# j7am_pulsar1_periph_switch_cbass0_ISC register map
Vendor: Texas Instruments
Peripheral module from a debugger description file (folder J721S2).
Registers are 32-bit, read-write, reset 0x0 unless marked. A register's access mark holds for its fields unless they carry their own. Offsets are as the file gives them; lines under a group give offsets from that group; [hi:lo] are bit positions; {n}, {i} and the like mark numbered series; 'fields as' and 'values as' point back to an identical list; <NAME> marks a mode.

## j7am_pulsar1_periph_switch_cbass0_ISC
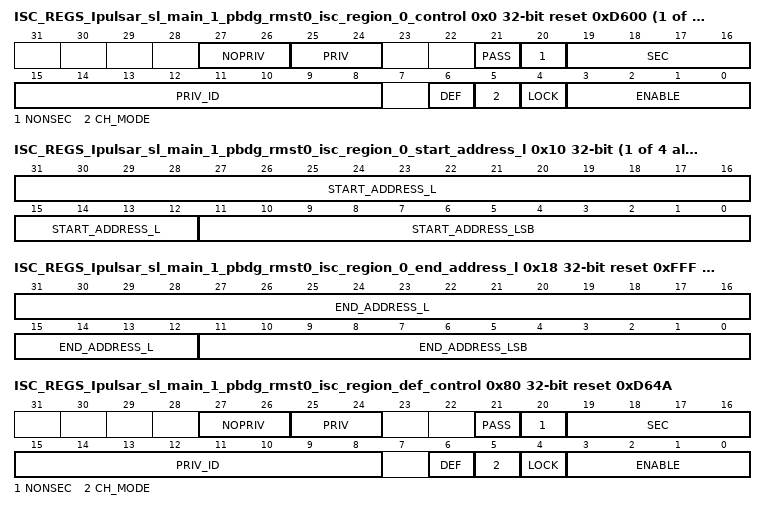
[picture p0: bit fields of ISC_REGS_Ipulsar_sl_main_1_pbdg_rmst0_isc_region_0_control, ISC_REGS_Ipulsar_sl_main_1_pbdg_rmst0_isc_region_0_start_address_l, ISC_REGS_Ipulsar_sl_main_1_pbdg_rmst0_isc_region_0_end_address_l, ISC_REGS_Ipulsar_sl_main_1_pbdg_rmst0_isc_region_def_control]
{0x0+0x20*i} ISC_REGS_Ipulsar_sl_main_1_pbdg_rmst0_isc_region_{i}_control access not given reset 0xD600 (i=0..3) — The ISC Region {i} Control Register defines the control fields for the master Ipulsar_sl_main_1.pbdg_rmst0 region {i} ISC.
  [27:26] NOPRIV rw — Clear output priv attribute. If each bit is set then the outgoing priv bit is cleared.
  [25:24] PRIV rw — Set outgoing priv attribute. If each bit is set then the outgoing priv bit is set.
  [21] PASS rw — No privID replacement, pass through value.
  [20] NONSEC rw — Make outgoing non-secure.
  [19:16] SEC rw — Make outgoing secure. A value of 0xA enables, others disable.
  [15:8] PRIV_ID rw
  [6] DEF ro — Default region indication. The default region is used when all other regions do not match.
  [5] CH_MODE rw — Enable channel mode to match region to a chanid value. Otherwise use address mode to match region to an address range.
  [4] LOCK — Lock region. Once set the region values cannot be modified. (access R/W1TS)
  [3:0] ENABLE rw — Enable region. A value of 0xA enables, others disable.
{0x10+0x20*i} ISC_REGS_Ipulsar_sl_main_1_pbdg_rmst0_isc_region_{i}_start_address_l (i=0..3) — The ISC Region {i} Start Address Low Register defines the start address bits 31 to 0 for the master Ipulsar_sl_main_1.pbdg_rmst0 region {i} ISC.
  [31:12] START_ADDRESS_L — Start address bits 31 to 12.
  [11:0] START_ADDRESS_LSB — Start address bits 11 to 0 must be 0 as address must be 4KB aligned in address mode. Can also be channel number in channel mode.
{0x14+0x20*i} ISC_REGS_Ipulsar_sl_main_1_pbdg_rmst0_isc_region_{i}_start_address_h (i=0..3) — The ISC Region {i} Start Address High Register defines the start address bits 47 to 32 for the master Ipulsar_sl_main_1.pbdg_rmst0 region {i} ISC.
  [15:0] START_ADDRESS_H — Start address bits 47 to 32.
{0x18+0x20*i} ISC_REGS_Ipulsar_sl_main_1_pbdg_rmst0_isc_region_{i}_end_address_l access per field reset 0xFFF (i=0..3) — The ISC Region {i} End Address Low Register defines the end included address bits 31 to 0 for the master Ipulsar_sl_main_1.pbdg_rmst0 region {i} ISC.
  [31:12] END_ADDRESS_L rw — End address bits 31 to 12 to include in the match.
  [11:0] END_ADDRESS_LSB ro — End address bits 11 to 0 are forced to Fs as address must be 4KB aligned.
{0x1C+0x20*i} ISC_REGS_Ipulsar_sl_main_1_pbdg_rmst0_isc_region_{i}_end_address_h (i=0..3) — The ISC Region {i} End Address High Register defines the end address bits 47 to 32 for the master Ipulsar_sl_main_1.pbdg_rmst0 region {i} ISC.
  [15:0] END_ADDRESS_H — End address bits 47 to 32.
0x80 ISC_REGS_Ipulsar_sl_main_1_pbdg_rmst0_isc_region_def_control access not given reset 0xD64A — The ISC Default Region Control Register defines the control fields for the master Ipulsar_sl_main_1.pbdg_rmst0 region 4 ISC.
  [27:26] NOPRIV rw — Clear output priv attribute. If each bit is set then the outgoing priv bit is cleared, else the bit is unchanged. Do not set both priv and nopriv for the same bit.
  [25:24] PRIV rw — Set outgoing priv attribute. If each bit is set then the outgoing priv bit is set, else the bit is unchanged. Do not set both priv and nopriv for the same bit.
  [21] PASS rw — No privID replacement. A value of 1 will pass through privid value. A value of 0 will replace privid with priv_id field value.
  [20] NONSEC rw — Make outgoing non-secure. A value of 1 forces secure clear, others do nothing. Do not set both sec and nonsec.
  [19:16] SEC rw — Make outgoing secure. A value of 0xA forces secure set, others do nothing. Do not set both sec and nonsec.
  [15:8] PRIV_ID rw — Priv ID value to use if pass is 0.
  [6] DEF ro — Default region indication. The default region is used when all other regions do not match.
  [5] CH_MODE ro — Enable channel mode to match region to a chanid value. Otherwise use address mode to match region to an address range.
  [4] LOCK — Lock region. Once set, the region values cannot be modified. (access R/W1TS)
  [3:0] ENABLE ro — Enable region. A value of 0xA enables, others disable.
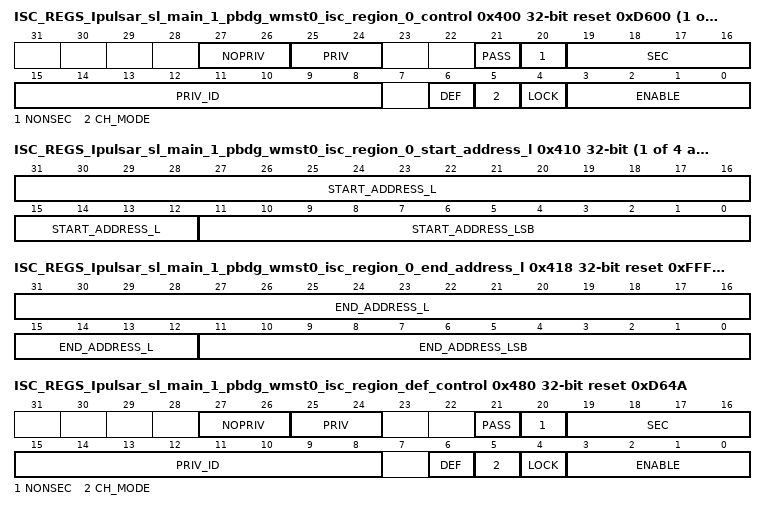
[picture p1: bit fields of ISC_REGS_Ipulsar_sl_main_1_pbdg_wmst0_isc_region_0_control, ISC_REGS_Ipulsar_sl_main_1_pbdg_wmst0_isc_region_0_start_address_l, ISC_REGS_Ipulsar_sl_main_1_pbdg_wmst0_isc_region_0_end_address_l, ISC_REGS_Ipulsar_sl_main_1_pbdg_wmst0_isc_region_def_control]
{0x400+0x20*i} ISC_REGS_Ipulsar_sl_main_1_pbdg_wmst0_isc_region_{i}_control access not given reset 0xD600 (i=0..3) — The ISC Region {i} Control Register defines the control fields for the master Ipulsar_sl_main_1.pbdg_wmst0 region {i} ISC.
  fields as ISC_REGS_Ipulsar_sl_main_1_pbdg_rmst0_isc_region_0_control
{0x410+0x20*i} ISC_REGS_Ipulsar_sl_main_1_pbdg_wmst0_isc_region_{i}_start_address_l (i=0..3) — The ISC Region {i} Start Address Low Register defines the start address bits 31 to 0 for the master Ipulsar_sl_main_1.pbdg_wmst0 region {i} ISC.
  fields as ISC_REGS_Ipulsar_sl_main_1_pbdg_rmst0_isc_region_0_start_address_l
{0x414+0x20*i} ISC_REGS_Ipulsar_sl_main_1_pbdg_wmst0_isc_region_{i}_start_address_h (i=0..3) — The ISC Region {i} Start Address High Register defines the start address bits 47 to 32 for the master Ipulsar_sl_main_1.pbdg_wmst0 region {i} ISC.
  [15:0] START_ADDRESS_H — Start address bits 47 to 32.
{0x418+0x20*i} ISC_REGS_Ipulsar_sl_main_1_pbdg_wmst0_isc_region_{i}_end_address_l access per field reset 0xFFF (i=0..3) — The ISC Region {i} End Address Low Register defines the end included address bits 31 to 0 for the master Ipulsar_sl_main_1.pbdg_wmst0 region {i} ISC.
  fields as ISC_REGS_Ipulsar_sl_main_1_pbdg_rmst0_isc_region_0_end_address_l
{0x41C+0x20*i} ISC_REGS_Ipulsar_sl_main_1_pbdg_wmst0_isc_region_{i}_end_address_h (i=0..3) — The ISC Region {i} End Address High Register defines the end address bits 47 to 32 for the master Ipulsar_sl_main_1.pbdg_wmst0 region {i} ISC.
  [15:0] END_ADDRESS_H — End address bits 47 to 32.
0x480 ISC_REGS_Ipulsar_sl_main_1_pbdg_wmst0_isc_region_def_control access not given reset 0xD64A — The ISC Default Region Control Register defines the control fields for the master Ipulsar_sl_main_1.pbdg_wmst0 region 4 ISC.
  fields as ISC_REGS_Ipulsar_sl_main_1_pbdg_rmst0_isc_region_def_control
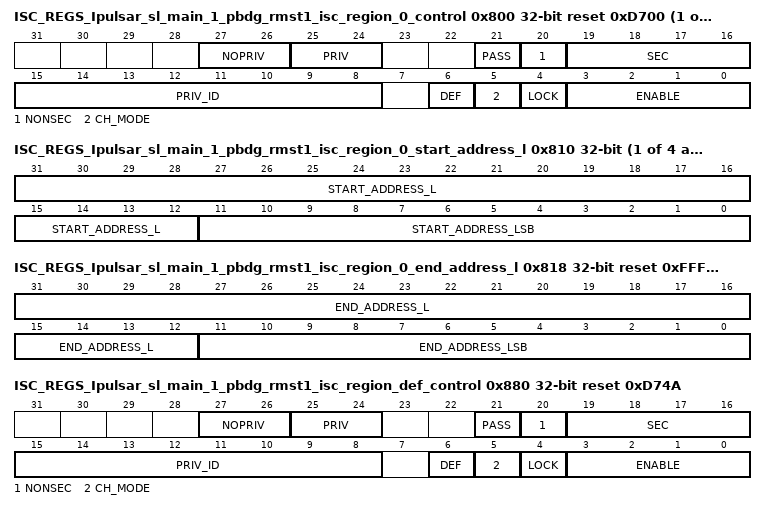
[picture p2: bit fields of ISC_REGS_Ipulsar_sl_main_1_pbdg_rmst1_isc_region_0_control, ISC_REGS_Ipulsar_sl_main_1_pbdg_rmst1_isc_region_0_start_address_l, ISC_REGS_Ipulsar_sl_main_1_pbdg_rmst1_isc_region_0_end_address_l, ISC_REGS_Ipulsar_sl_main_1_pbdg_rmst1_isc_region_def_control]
{0x800+0x20*i} ISC_REGS_Ipulsar_sl_main_1_pbdg_rmst1_isc_region_{i}_control access not given reset 0xD700 (i=0..3) — The ISC Region {i} Control Register defines the control fields for the master Ipulsar_sl_main_1.pbdg_rmst1 region {i} ISC.
  fields as ISC_REGS_Ipulsar_sl_main_1_pbdg_rmst0_isc_region_0_control
{0x810+0x20*i} ISC_REGS_Ipulsar_sl_main_1_pbdg_rmst1_isc_region_{i}_start_address_l (i=0..3) — The ISC Region {i} Start Address Low Register defines the start address bits 31 to 0 for the master Ipulsar_sl_main_1.pbdg_rmst1 region {i} ISC.
  fields as ISC_REGS_Ipulsar_sl_main_1_pbdg_rmst0_isc_region_0_start_address_l
{0x814+0x20*i} ISC_REGS_Ipulsar_sl_main_1_pbdg_rmst1_isc_region_{i}_start_address_h (i=0..3) — The ISC Region {i} Start Address High Register defines the start address bits 47 to 32 for the master Ipulsar_sl_main_1.pbdg_rmst1 region {i} ISC.
  [15:0] START_ADDRESS_H — Start address bits 47 to 32.
{0x818+0x20*i} ISC_REGS_Ipulsar_sl_main_1_pbdg_rmst1_isc_region_{i}_end_address_l access per field reset 0xFFF (i=0..3) — The ISC Region {i} End Address Low Register defines the end included address bits 31 to 0 for the master Ipulsar_sl_main_1.pbdg_rmst1 region {i} ISC.
  fields as ISC_REGS_Ipulsar_sl_main_1_pbdg_rmst0_isc_region_0_end_address_l
{0x81C+0x20*i} ISC_REGS_Ipulsar_sl_main_1_pbdg_rmst1_isc_region_{i}_end_address_h (i=0..3) — The ISC Region {i} End Address High Register defines the end address bits 47 to 32 for the master Ipulsar_sl_main_1.pbdg_rmst1 region {i} ISC.
  [15:0] END_ADDRESS_H — End address bits 47 to 32.
0x880 ISC_REGS_Ipulsar_sl_main_1_pbdg_rmst1_isc_region_def_control access not given reset 0xD74A — The ISC Default Region Control Register defines the control fields for the master Ipulsar_sl_main_1.pbdg_rmst1 region 4 ISC.
  fields as ISC_REGS_Ipulsar_sl_main_1_pbdg_rmst0_isc_region_def_control
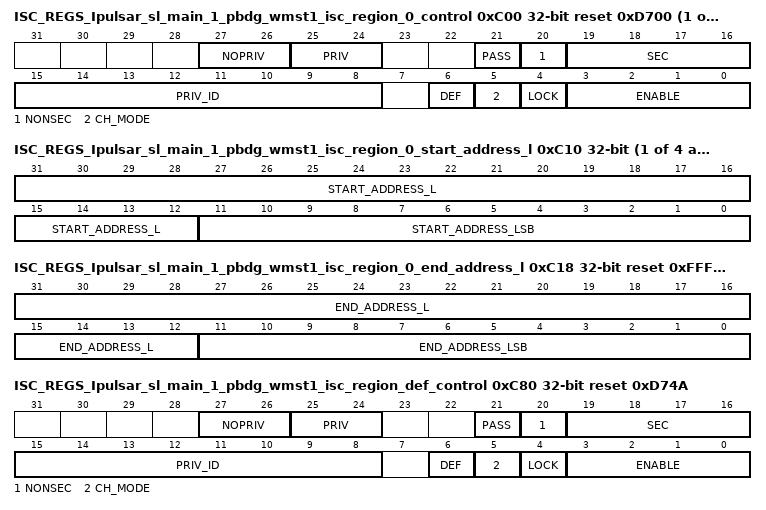
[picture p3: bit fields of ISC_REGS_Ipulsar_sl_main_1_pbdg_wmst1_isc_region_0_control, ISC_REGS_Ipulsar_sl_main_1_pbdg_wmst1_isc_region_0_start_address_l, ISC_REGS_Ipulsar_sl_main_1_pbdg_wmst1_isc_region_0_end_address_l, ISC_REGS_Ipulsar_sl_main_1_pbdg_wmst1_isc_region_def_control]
{0xC00+0x20*i} ISC_REGS_Ipulsar_sl_main_1_pbdg_wmst1_isc_region_{i}_control access not given reset 0xD700 (i=0..3) — The ISC Region {i} Control Register defines the control fields for the master Ipulsar_sl_main_1.pbdg_wmst1 region {i} ISC.
  fields as ISC_REGS_Ipulsar_sl_main_1_pbdg_rmst0_isc_region_0_control
{0xC10+0x20*i} ISC_REGS_Ipulsar_sl_main_1_pbdg_wmst1_isc_region_{i}_start_address_l (i=0..3) — The ISC Region {i} Start Address Low Register defines the start address bits 31 to 0 for the master Ipulsar_sl_main_1.pbdg_wmst1 region {i} ISC.
  fields as ISC_REGS_Ipulsar_sl_main_1_pbdg_rmst0_isc_region_0_start_address_l
{0xC14+0x20*i} ISC_REGS_Ipulsar_sl_main_1_pbdg_wmst1_isc_region_{i}_start_address_h (i=0..3) — The ISC Region {i} Start Address High Register defines the start address bits 47 to 32 for the master Ipulsar_sl_main_1.pbdg_wmst1 region {i} ISC.
  [15:0] START_ADDRESS_H — Start address bits 47 to 32.
{0xC18+0x20*i} ISC_REGS_Ipulsar_sl_main_1_pbdg_wmst1_isc_region_{i}_end_address_l access per field reset 0xFFF (i=0..3) — The ISC Region {i} End Address Low Register defines the end included address bits 31 to 0 for the master Ipulsar_sl_main_1.pbdg_wmst1 region {i} ISC.
  fields as ISC_REGS_Ipulsar_sl_main_1_pbdg_rmst0_isc_region_0_end_address_l
{0xC1C+0x20*i} ISC_REGS_Ipulsar_sl_main_1_pbdg_wmst1_isc_region_{i}_end_address_h (i=0..3) — The ISC Region {i} End Address High Register defines the end address bits 47 to 32 for the master Ipulsar_sl_main_1.pbdg_wmst1 region {i} ISC.
  [15:0] END_ADDRESS_H — End address bits 47 to 32.
0xC80 ISC_REGS_Ipulsar_sl_main_1_pbdg_wmst1_isc_region_def_control access not given reset 0xD74A — The ISC Default Region Control Register defines the control fields for the master Ipulsar_sl_main_1.pbdg_wmst1 region 4 ISC.
  fields as ISC_REGS_Ipulsar_sl_main_1_pbdg_rmst0_isc_region_def_control
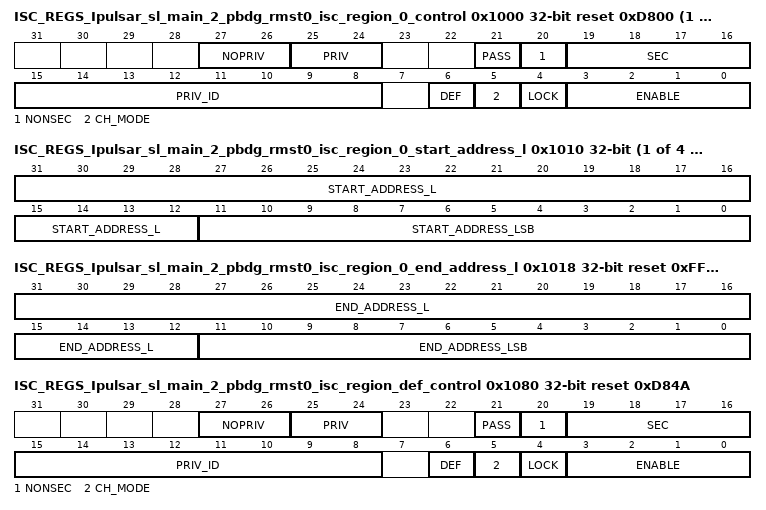
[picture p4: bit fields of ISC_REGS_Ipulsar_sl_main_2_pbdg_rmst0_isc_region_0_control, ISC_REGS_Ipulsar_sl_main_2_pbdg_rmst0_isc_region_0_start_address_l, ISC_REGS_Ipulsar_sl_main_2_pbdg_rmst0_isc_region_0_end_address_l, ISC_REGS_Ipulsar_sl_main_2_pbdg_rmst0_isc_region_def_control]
{0x1000+0x20*i} ISC_REGS_Ipulsar_sl_main_2_pbdg_rmst0_isc_region_{i}_control access not given reset 0xD800 (i=0..3) — The ISC Region {i} Control Register defines the control fields for the master Ipulsar_sl_main_2.pbdg_rmst0 region {i} ISC.
  fields as ISC_REGS_Ipulsar_sl_main_1_pbdg_rmst0_isc_region_0_control
{0x1010+0x20*i} ISC_REGS_Ipulsar_sl_main_2_pbdg_rmst0_isc_region_{i}_start_address_l (i=0..3) — The ISC Region {i} Start Address Low Register defines the start address bits 31 to 0 for the master Ipulsar_sl_main_2.pbdg_rmst0 region {i} ISC.
  fields as ISC_REGS_Ipulsar_sl_main_1_pbdg_rmst0_isc_region_0_start_address_l
{0x1014+0x20*i} ISC_REGS_Ipulsar_sl_main_2_pbdg_rmst0_isc_region_{i}_start_address_h (i=0..3) — The ISC Region {i} Start Address High Register defines the start address bits 47 to 32 for the master Ipulsar_sl_main_2.pbdg_rmst0 region {i} ISC.
  [15:0] START_ADDRESS_H — Start address bits 47 to 32.
{0x1018+0x20*i} ISC_REGS_Ipulsar_sl_main_2_pbdg_rmst0_isc_region_{i}_end_address_l access per field reset 0xFFF (i=0..3) — The ISC Region {i} End Address Low Register defines the end included address bits 31 to 0 for the master Ipulsar_sl_main_2.pbdg_rmst0 region {i} ISC.
  fields as ISC_REGS_Ipulsar_sl_main_1_pbdg_rmst0_isc_region_0_end_address_l
{0x101C+0x20*i} ISC_REGS_Ipulsar_sl_main_2_pbdg_rmst0_isc_region_{i}_end_address_h (i=0..3) — The ISC Region {i} End Address High Register defines the end address bits 47 to 32 for the master Ipulsar_sl_main_2.pbdg_rmst0 region {i} ISC.
  [15:0] END_ADDRESS_H — End address bits 47 to 32.
0x1080 ISC_REGS_Ipulsar_sl_main_2_pbdg_rmst0_isc_region_def_control access not given reset 0xD84A — The ISC Default Region Control Register defines the control fields for the master Ipulsar_sl_main_2.pbdg_rmst0 region 4 ISC.
  fields as ISC_REGS_Ipulsar_sl_main_1_pbdg_rmst0_isc_region_def_control
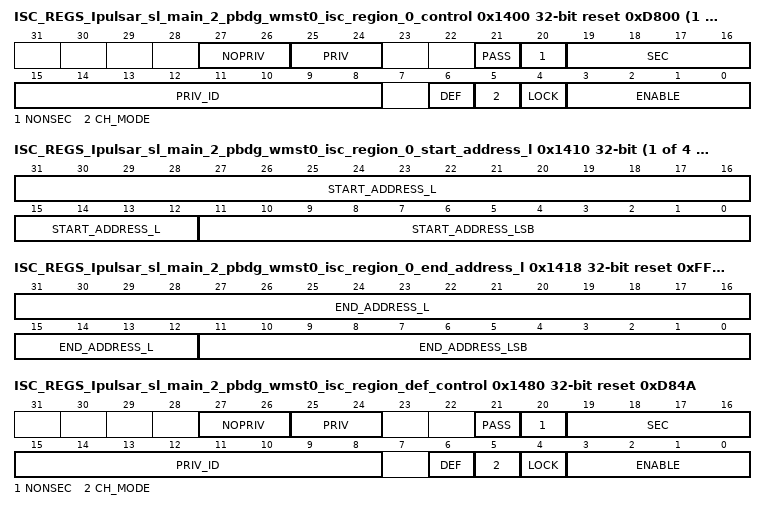
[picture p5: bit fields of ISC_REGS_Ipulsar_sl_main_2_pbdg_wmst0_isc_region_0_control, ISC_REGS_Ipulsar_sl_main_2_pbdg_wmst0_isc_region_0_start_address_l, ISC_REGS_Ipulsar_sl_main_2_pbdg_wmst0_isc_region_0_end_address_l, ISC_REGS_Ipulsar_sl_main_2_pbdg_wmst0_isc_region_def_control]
{0x1400+0x20*i} ISC_REGS_Ipulsar_sl_main_2_pbdg_wmst0_isc_region_{i}_control access not given reset 0xD800 (i=0..3) — The ISC Region {i} Control Register defines the control fields for the master Ipulsar_sl_main_2.pbdg_wmst0 region {i} ISC.
  fields as ISC_REGS_Ipulsar_sl_main_1_pbdg_rmst0_isc_region_0_control
{0x1410+0x20*i} ISC_REGS_Ipulsar_sl_main_2_pbdg_wmst0_isc_region_{i}_start_address_l (i=0..3) — The ISC Region {i} Start Address Low Register defines the start address bits 31 to 0 for the master Ipulsar_sl_main_2.pbdg_wmst0 region {i} ISC.
  fields as ISC_REGS_Ipulsar_sl_main_1_pbdg_rmst0_isc_region_0_start_address_l
{0x1414+0x20*i} ISC_REGS_Ipulsar_sl_main_2_pbdg_wmst0_isc_region_{i}_start_address_h (i=0..3) — The ISC Region {i} Start Address High Register defines the start address bits 47 to 32 for the master Ipulsar_sl_main_2.pbdg_wmst0 region {i} ISC.
  [15:0] START_ADDRESS_H — Start address bits 47 to 32.
{0x1418+0x20*i} ISC_REGS_Ipulsar_sl_main_2_pbdg_wmst0_isc_region_{i}_end_address_l access per field reset 0xFFF (i=0..3) — The ISC Region {i} End Address Low Register defines the end included address bits 31 to 0 for the master Ipulsar_sl_main_2.pbdg_wmst0 region {i} ISC.
  fields as ISC_REGS_Ipulsar_sl_main_1_pbdg_rmst0_isc_region_0_end_address_l
{0x141C+0x20*i} ISC_REGS_Ipulsar_sl_main_2_pbdg_wmst0_isc_region_{i}_end_address_h (i=0..3) — The ISC Region {i} End Address High Register defines the end address bits 47 to 32 for the master Ipulsar_sl_main_2.pbdg_wmst0 region {i} ISC.
  [15:0] END_ADDRESS_H — End address bits 47 to 32.
0x1480 ISC_REGS_Ipulsar_sl_main_2_pbdg_wmst0_isc_region_def_control access not given reset 0xD84A — The ISC Default Region Control Register defines the control fields for the master Ipulsar_sl_main_2.pbdg_wmst0 region 4 ISC.
  fields as ISC_REGS_Ipulsar_sl_main_1_pbdg_rmst0_isc_region_def_control
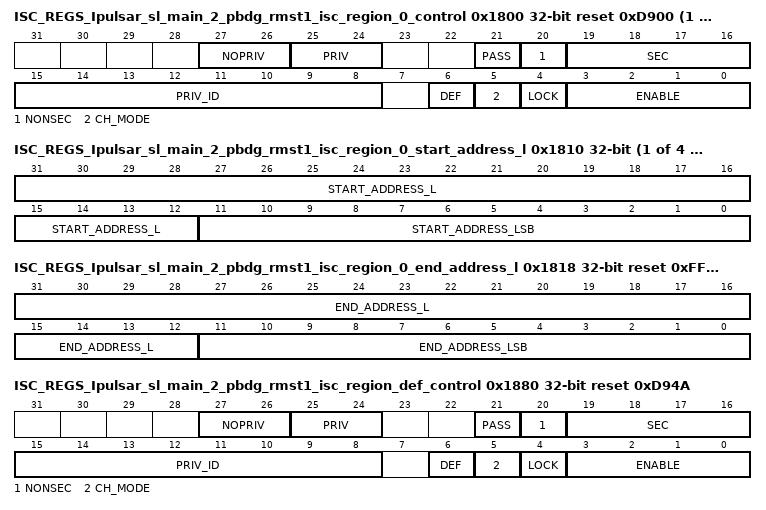
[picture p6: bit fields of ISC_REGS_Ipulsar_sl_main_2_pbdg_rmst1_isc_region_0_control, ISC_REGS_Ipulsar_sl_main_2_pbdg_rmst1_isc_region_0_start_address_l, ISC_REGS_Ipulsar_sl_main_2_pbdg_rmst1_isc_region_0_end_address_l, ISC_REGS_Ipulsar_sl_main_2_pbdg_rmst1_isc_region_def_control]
{0x1800+0x20*i} ISC_REGS_Ipulsar_sl_main_2_pbdg_rmst1_isc_region_{i}_control access not given reset 0xD900 (i=0..3) — The ISC Region {i} Control Register defines the control fields for the master Ipulsar_sl_main_2.pbdg_rmst1 region {i} ISC.
  fields as ISC_REGS_Ipulsar_sl_main_1_pbdg_rmst0_isc_region_0_control
{0x1810+0x20*i} ISC_REGS_Ipulsar_sl_main_2_pbdg_rmst1_isc_region_{i}_start_address_l (i=0..3) — The ISC Region {i} Start Address Low Register defines the start address bits 31 to 0 for the master Ipulsar_sl_main_2.pbdg_rmst1 region {i} ISC.
  fields as ISC_REGS_Ipulsar_sl_main_1_pbdg_rmst0_isc_region_0_start_address_l
{0x1814+0x20*i} ISC_REGS_Ipulsar_sl_main_2_pbdg_rmst1_isc_region_{i}_start_address_h (i=0..3) — The ISC Region {i} Start Address High Register defines the start address bits 47 to 32 for the master Ipulsar_sl_main_2.pbdg_rmst1 region {i} ISC.
  [15:0] START_ADDRESS_H — Start address bits 47 to 32.
{0x1818+0x20*i} ISC_REGS_Ipulsar_sl_main_2_pbdg_rmst1_isc_region_{i}_end_address_l access per field reset 0xFFF (i=0..3) — The ISC Region {i} End Address Low Register defines the end included address bits 31 to 0 for the master Ipulsar_sl_main_2.pbdg_rmst1 region {i} ISC.
  fields as ISC_REGS_Ipulsar_sl_main_1_pbdg_rmst0_isc_region_0_end_address_l
{0x181C+0x20*i} ISC_REGS_Ipulsar_sl_main_2_pbdg_rmst1_isc_region_{i}_end_address_h (i=0..3) — The ISC Region {i} End Address High Register defines the end address bits 47 to 32 for the master Ipulsar_sl_main_2.pbdg_rmst1 region {i} ISC.
  [15:0] END_ADDRESS_H — End address bits 47 to 32.
0x1880 ISC_REGS_Ipulsar_sl_main_2_pbdg_rmst1_isc_region_def_control access not given reset 0xD94A — The ISC Default Region Control Register defines the control fields for the master Ipulsar_sl_main_2.pbdg_rmst1 region 4 ISC.
  fields as ISC_REGS_Ipulsar_sl_main_1_pbdg_rmst0_isc_region_def_control
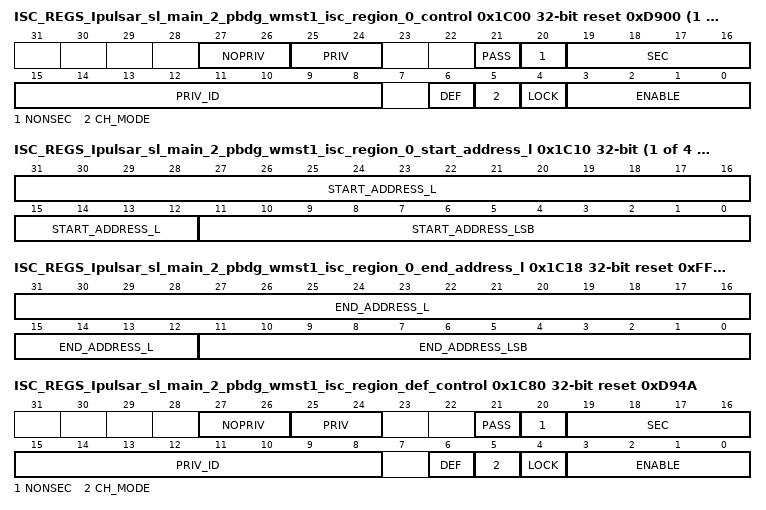
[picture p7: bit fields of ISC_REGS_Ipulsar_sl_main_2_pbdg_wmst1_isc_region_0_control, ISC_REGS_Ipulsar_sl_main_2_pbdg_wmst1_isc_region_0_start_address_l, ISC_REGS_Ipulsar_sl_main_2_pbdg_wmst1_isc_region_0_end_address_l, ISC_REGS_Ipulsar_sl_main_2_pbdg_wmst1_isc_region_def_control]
{0x1C00+0x20*i} ISC_REGS_Ipulsar_sl_main_2_pbdg_wmst1_isc_region_{i}_control access not given reset 0xD900 (i=0..3) — The ISC Region {i} Control Register defines the control fields for the master Ipulsar_sl_main_2.pbdg_wmst1 region {i} ISC.
  fields as ISC_REGS_Ipulsar_sl_main_1_pbdg_rmst0_isc_region_0_control
{0x1C10+0x20*i} ISC_REGS_Ipulsar_sl_main_2_pbdg_wmst1_isc_region_{i}_start_address_l (i=0..3) — The ISC Region {i} Start Address Low Register defines the start address bits 31 to 0 for the master Ipulsar_sl_main_2.pbdg_wmst1 region {i} ISC.
  fields as ISC_REGS_Ipulsar_sl_main_1_pbdg_rmst0_isc_region_0_start_address_l
{0x1C14+0x20*i} ISC_REGS_Ipulsar_sl_main_2_pbdg_wmst1_isc_region_{i}_start_address_h (i=0..3) — The ISC Region {i} Start Address High Register defines the start address bits 47 to 32 for the master Ipulsar_sl_main_2.pbdg_wmst1 region {i} ISC.
  [15:0] START_ADDRESS_H — Start address bits 47 to 32.
{0x1C18+0x20*i} ISC_REGS_Ipulsar_sl_main_2_pbdg_wmst1_isc_region_{i}_end_address_l access per field reset 0xFFF (i=0..3) — The ISC Region {i} End Address Low Register defines the end included address bits 31 to 0 for the master Ipulsar_sl_main_2.pbdg_wmst1 region {i} ISC.
  fields as ISC_REGS_Ipulsar_sl_main_1_pbdg_rmst0_isc_region_0_end_address_l
{0x1C1C+0x20*i} ISC_REGS_Ipulsar_sl_main_2_pbdg_wmst1_isc_region_{i}_end_address_h (i=0..3) — The ISC Region {i} End Address High Register defines the end address bits 47 to 32 for the master Ipulsar_sl_main_2.pbdg_wmst1 region {i} ISC.
  [15:0] END_ADDRESS_H — End address bits 47 to 32.
0x1C80 ISC_REGS_Ipulsar_sl_main_2_pbdg_wmst1_isc_region_def_control access not given reset 0xD94A — The ISC Default Region Control Register defines the control fields for the master Ipulsar_sl_main_2.pbdg_wmst1 region 4 ISC.
  fields as ISC_REGS_Ipulsar_sl_main_1_pbdg_rmst0_isc_region_def_control
